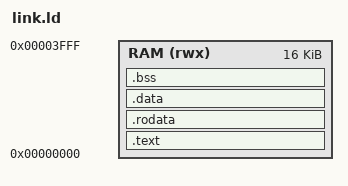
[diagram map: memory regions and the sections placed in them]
/* link.ld - everything lives in the one 16 KiB RAM starting at 0 */

OUTPUT_ARCH("riscv")
ENTRY(_start)

MEMORY
{
    RAM (rwx) : ORIGIN = 0x00000000, LENGTH = 16K
}

SECTIONS
{
    .text : {
        KEEP(*(.text.start))
        *(.text .text.*)
    } > RAM

    .rodata : ALIGN(4) {
        *(.rodata .rodata.* .srodata .srodata.*)
    } > RAM

    .data : ALIGN(4) {
        __global_pointer$ = . + 0x800;
        *(.sdata .sdata.* .data .data.*)
    } > RAM

    .bss (NOLOAD) : ALIGN(4) {
        __bss_start = .;
        *(.sbss .sbss.* .bss .bss.* COMMON)
        . = ALIGN(4);
        __bss_end = .;
    } > RAM

    __stack_top = ORIGIN(RAM) + LENGTH(RAM);

    /DISCARD/ : { *(.comment) *(.riscv.attributes) *(.note*) }
}
